VERSION ""

NS_ :

BS_:

BU_:

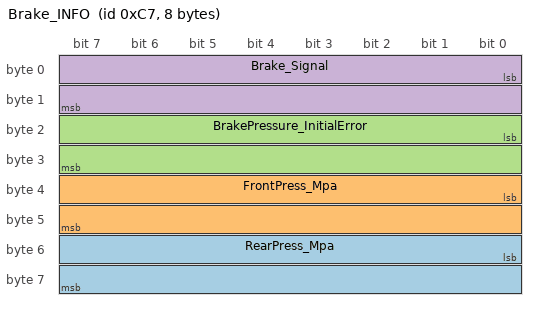
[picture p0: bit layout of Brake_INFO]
BO_ 199 Brake_INFO: 8 Vector__XXX
 SG_ RearPress_Mpa : 48|16@1+ (0.01,0) [0|655.35] "" Vector__XXX
 SG_ FrontPress_Mpa : 32|16@1+ (0.01,0) [0|655.35] "" Vector__XXX
 SG_ BrakePressure_InitialError : 16|16@1- (1,0) [-32768|32767] "" Vector__XXX
 SG_ Brake_Signal : 0|16@1- (1,0) [-32768|32767] "" Vector__XXX

BA_DEF_  "BusType" STRING ;
BA_DEF_DEF_  "BusType" "CAN";
